VERSION ""

NS_ :

BS_:

BU_: PDM ATCCR ATCCF

BO_ 3221225472 VECTOR__INDEPENDENT_SIG_MSG: 0 Vector__XXX
 SG_ ATCCF_counterMsg415 : 0|4@1+ (1,0) [0|15] "" Vector__XXX
 SG_ ATCCF_counterMsg414 : 0|4@1+ (1,0) [0|15] "" Vector__XXX
 SG_ ATCCF_counterMsg413 : 0|4@1+ (1,0) [0|15] "" Vector__XXX
 SG_ ATCCF_counterMsg412 : 0|4@1+ (1,0) [0|15] "" Vector__XXX
 SG_ ATCCF_counterMsg411 : 0|4@1+ (1,0) [0|15] "" Vector__XXX
 SG_ PDM_pdmCurrentMin : 0|16@1- (0.01,0) [-327.68|327.67] "A" Vector__XXX
 SG_ PDM_pdmCurrentAvg : 0|16@1- (0.01,0) [-327.68|327.67] "A" Vector__XXX
 SG_ PDM_pdmCurrentMax : 0|16@1- (0.01,0) [-327.68|327.67] "A" Vector__XXX
 SG_ PDM_boardTemp : 0|16@1- (0.1,0) [-3276.8|3276.7] "C" Vector__XXX
 SG_ ATCCR_tireTempRRO : 0|16@1- (1,0) [-32768|32767] "" Vector__XXX
 SG_ ATCCR_tireTempRRM : 0|16@1- (1,0) [-32768|32767] "" Vector__XXX
 SG_ ATCCR_tireTempRRI : 0|16@1- (1,0) [-32768|32767] "" Vector__XXX
 SG_ ATCCR_tireTempRLO : 0|16@1- (1,0) [-32768|32767] "" Vector__XXX
 SG_ ATCCR_tireTempRLM : 0|16@1- (1,0) [-32768|32767] "" Vector__XXX
 SG_ ATCCR_tireTempRLI : 0|16@1- (1,0) [-32768|32767] "" Vector__XXX
 SG_ ATCCR_suspensionTravelRR : 0|16@1- (1,0) [-32768|32767] "" Vector__XXX
 SG_ ATCCR_suspensionTravelRL : 0|16@1- (1,0) [-32768|32767] "" Vector__XXX
 SG_ ATCCR_coolantTempRadOutlet : 0|16@1- (1,0) [-32768|32767] "" Vector__XXX
 SG_ ATCCR_coolantTempRadInlet : 0|16@1- (1,0) [-32768|32767] "" Vector__XXX
 SG_ ATCCR_brakeTempRR : 0|16@1- (1,0) [-32768|32767] "" Vector__XXX
 SG_ ATCCR_brakeTempRL : 0|16@1- (1,0) [-32768|32767] "" Vector__XXX
 SG_ ATCCR_boardTemp : 0|16@1- (1,0) [-32768|32767] "" Vector__XXX
 SG_ ATCCF_tireTempFRO : 0|16@1- (1,0) [-32768|32767] "" Vector__XXX
 SG_ ATCCF_tireTempFRM : 0|16@1- (1,0) [-32768|32767] "" Vector__XXX
 SG_ ATCCF_tireTempFRI : 0|16@1- (1,0) [-32768|32767] "" Vector__XXX
 SG_ ATCCF_tireTempFLO : 0|16@1- (1,0) [-32768|32767] "" Vector__XXX
 SG_ ATCCF_tireTempFLM : 0|16@1- (1,0) [-32768|32767] "" Vector__XXX
 SG_ ATCCF_tireTempFLI : 0|16@1- (1,0) [-32768|32767] "" Vector__XXX
 SG_ ATCCF_steeringWheelAngle : 0|16@1- (1,0) [-32768|32767] "" Vector__XXX
 SG_ ATCCF_coolantTempRadMiddle : 0|16@1- (1,0) [-32768|32767] "" Vector__XXX
 SG_ ATCCF_brakeTempFR : 0|16@1- (1,0) [-32768|32767] "" Vector__XXX
 SG_ ATCCF_brakeTempFL : 0|16@1- (1,0) [-32768|32767] "" Vector__XXX
 SG_ ATCCF_brakePressureR : 0|16@1- (1,0) [-32768|32767] "" Vector__XXX
 SG_ ATCCF_brakePressureF : 0|16@1- (1,0) [-32768|32767] "" Vector__XXX

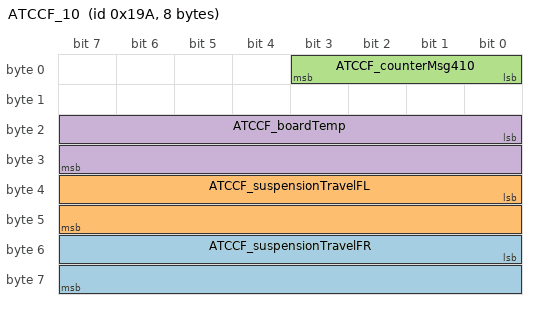
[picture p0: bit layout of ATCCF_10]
BO_ 410 ATCCF_10: 8 ATCCF
 SG_ ATCCF_suspensionTravelFR : 48|16@1- (1,0) [-32768|32767] "" Vector__XXX
 SG_ ATCCF_suspensionTravelFL : 32|16@1- (1,0) [-32768|32767] "" Vector__XXX
 SG_ ATCCF_counterMsg410 : 0|4@1+ (1,0) [0|15] "" Vector__XXX
 SG_ ATCCF_boardTemp : 16|16@1- (1,0) [-32768|32767] "" Vector__XXX

CM_ BO_ 3221225472 "This is a message for not used signals, created by Vector CANdb++ DBC OLE DB Provider.";
CM_ SG_ 3221225472 ATCCR_tireTempRRO "Tire Temp RRO";
CM_ SG_ 3221225472 ATCCR_tireTempRRM "Tire Temp RRM";
CM_ SG_ 3221225472 ATCCR_tireTempRRI "Tire Temp RRI";
CM_ SG_ 3221225472 ATCCR_tireTempRLO "Tire Temp RLO";
CM_ SG_ 3221225472 ATCCR_tireTempRLM "Tire Temp RLM";
CM_ SG_ 3221225472 ATCCR_tireTempRLI "Tire Temp RLI";
CM_ SG_ 3221225472 ATCCR_suspensionTravelRR "Suspension Travel RR";
CM_ SG_ 3221225472 ATCCR_suspensionTravelRL "Suspension Travel RL";
CM_ SG_ 3221225472 ATCCR_coolantTempRadOutlet "Coolant Temp Radiator Outlet";
CM_ SG_ 3221225472 ATCCR_coolantTempRadInlet "Coolant Temp Radiator Inlet";
CM_ SG_ 3221225472 ATCCR_brakeTempRR "Brake Temp RR";
CM_ SG_ 3221225472 ATCCR_brakeTempRL "Brake Temp RL";
CM_ SG_ 3221225472 ATCCR_boardTemp "Board Temp";
CM_ SG_ 3221225472 ATCCF_tireTempFRO "Tire Temp FRO";
CM_ SG_ 3221225472 ATCCF_tireTempFRM "Tire Temp FRM";
CM_ SG_ 3221225472 ATCCF_tireTempFRI "Tire Temp FRI";
CM_ SG_ 3221225472 ATCCF_tireTempFLO "Tire Temp FLO";
CM_ SG_ 3221225472 ATCCF_tireTempFLM "Tire Temp FLM";
CM_ SG_ 3221225472 ATCCF_tireTempFLI "Tire Temp FLI";
CM_ SG_ 3221225472 ATCCF_steeringWheelAngle "Steering Wheel Angle";
CM_ SG_ 3221225472 ATCCF_coolantTempRadMiddle "Coolant Temp Radiator Middle";
CM_ SG_ 3221225472 ATCCF_brakeTempFR "Brake Temp FR";
CM_ SG_ 3221225472 ATCCF_brakeTempFL "Brake Temp FL";
CM_ SG_ 3221225472 ATCCF_brakePressureR "Brake Pressure R";
CM_ SG_ 3221225472 ATCCF_brakePressureF "Brake Pressure F";
CM_ SG_ 410 ATCCF_suspensionTravelFR "Suspension Travel FR";
CM_ SG_ 410 ATCCF_suspensionTravelFL "Suspension Travel FL";
CM_ SG_ 410 ATCCF_boardTemp "Board Temp";
BA_DEF_  "BusType" STRING ;
BA_DEF_DEF_  "BusType" "CAN";
